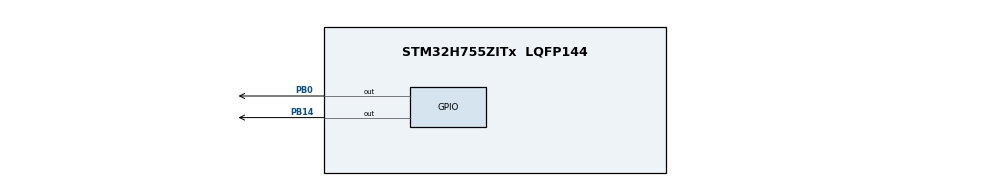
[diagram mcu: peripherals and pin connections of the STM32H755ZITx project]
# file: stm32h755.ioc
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Mcu.Family=STM32H7
PB14.PinAttribute=CortexM4
RCC.PLLSourceVirtual=RCC_PLLSOURCE_CSI
RCC.CortexFreq_Value=76000000
RCC.DIVQ1=4
CortexM4.Pins=PB14
NVIC1.PriorityGroup=NVIC_PRIORITYGROUP_4
RCC.SYSCLKSource=RCC_SYSCLKSOURCE_PLLCLK
ProjectManager.StackSize=0x400
ProjectManager.TargetToolchain=STM32CubeIDE
RCC.HCLKFreq_Value=76000000
RCC.DIVN1=38
RCC.USBFreq_Value=38000000
PB0.PinAttribute=CortexM7
PB14.Signal=GPIO_Output
RCC.HSE_VALUE=8000000
board=NUCLEO-H755ZI-Q
RCC.DIVM1=1
RCC.APB2Freq_Value=76000000
NVIC2.PriorityGroup=NVIC_PRIORITYGROUP_4
RCC.ADCFreq_Value=8062500
VP_SYS_M4_VS_Systick.Mode=SysTick
CortexM7.Pins=PB0
CortexM7.IPs=FATFS_M7\:I,FREERTOS_M7\:I,IWDG1\:I,RCC\:I,WWDG1\:I,DMA\:I,BDMA\:I,MDMA\:I,NVIC1\:I,ETH\:I,USART3\:I,USB_OTG_FS\:I,SYS\:I,CORTEX_M7\:I,DEBUG\:I,USB_DEVICE_M7\:I,USB_HOST_M7\:I,PDM2PCM_M7\:I,PWR\:I,RESMGR_UTILITY\:I,OPENAMP_M7\:I,VREFBUF\:I
Mcu.Name=STM32H755ZITx
RCC.APB3Freq_Value=76000000
RCC.SYSCLKFreq_VALUE=76000000
Mcu.Package=LQFP144
ProjectManager.HeapSize=0x200
RCC.APB4Freq_Value=76000000
RCC.APB1Freq_Value=76000000
PB0.Signal=GPIO_Output
RCC.SupplySource=PWR_DIRECT_SMPS_SUPPLY
CortexM4.IPs=FATFS_M4\:I,FREERTOS_M4\:I,IWDG2\:I,RCC,WWDG2\:I,DMA,BDMA,MDMA,NVIC2\:I,ETH,USART3,DEBUG,USB_DEVICE_M4\:I,USB_HOST_M4\:I,PDM2PCM_M4\:I,PWR,RESMGR_UTILITY,SYS_M4\:I,CORTEX_M4\:I,OPENAMP_M4\:I,VREFBUF

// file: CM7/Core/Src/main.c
/* USER CODE BEGIN Header */
/**
 ******************************************************************************
 * @file           : main.c
 * @brief          : Main program body
 ******************************************************************************
 * @attention
 *
 * <h2><center>&copy; Copyright (c) 2021 STMicroelectronics.
 * All rights reserved.</center></h2>
 *
 * This software component is licensed by ST under BSD 3-Clause license,
 * the "License"; You may not use this file except in compliance with the
 * License. You may obtain a copy of the License at:
 *                        opensource.org/licenses/BSD-3-Clause
 *
 ******************************************************************************
 */
/* USER CODE END Header */
#include "main.h"

/* USER CODE BEGIN PD */

#ifndef HSEM_ID_0
#define HSEM_ID_0 (0U) /* HW semaphore 0*/
#endif
/* USER CODE END PD */

void SystemClock_Config(void);
static void MX_GPIO_Init(void);

int main(void)
{
    /* USER CODE BEGIN Boot_Mode_Sequence_0 */
    int32_t timeout;
    /* USER CODE END Boot_Mode_Sequence_0 */

    /* USER CODE BEGIN Boot_Mode_Sequence_1 */
    /* Wait until CPU2 boots and enters in stop mode or timeout*/
    timeout = 0xFFFF;
    /*
    while ((__HAL_RCC_GET_FLAG(RCC_FLAG_D2CKRDY) != RESET) && (timeout-- > 0))
        ;
    if (timeout < 0)
    {
        Error_Handler();
    }
    */
    /* USER CODE END Boot_Mode_Sequence_1 */
    /* MCU Configuration--------------------------------------------------------*/

    /* Reset of all peripherals, Initializes the Flash interface and the Systick. */
    HAL_Init();

    /* Configure the system clock */
    SystemClock_Config();
    /* USER CODE BEGIN Boot_Mode_Sequence_2 */
    /* When system initialization is finished, Cortex-M7 will release Cortex-M4 by means of
    HSEM notification */
    /*HW semaphore Clock enable*/
    __HAL_RCC_HSEM_CLK_ENABLE();
    /*Take HSEM */
    HAL_HSEM_FastTake(HSEM_ID_0);
    /*Release HSEM in order to notify the CPU2(CM4)*/
    HAL_HSEM_Release(HSEM_ID_0, 0);
    /* wait until CPU2 wakes up from stop mode */
    timeout = 0xFFFF;
    while ((__HAL_RCC_GET_FLAG(RCC_FLAG_D2CKRDY) == RESET) && (timeout-- > 0))
        ;
    if (timeout < 0)
    {
        Error_Handler();
    }
    /* USER CODE END Boot_Mode_Sequence_2 */

    /* USER CODE BEGIN SysInit */
    GPIO_InitTypeDef GPIO_InitStruct = {0};

    /* GPIO Ports Clock Enable */
    __HAL_RCC_GPIOB_CLK_ENABLE();

    /*Configure GPIO pin Output Level */
    HAL_GPIO_WritePin(GPIOB, GPIO_PIN_0, GPIO_PIN_RESET);

    /*Configure GPIO pin : PB0 */
    GPIO_InitStruct.Pin = GPIO_PIN_0;
    GPIO_InitStruct.Mode = GPIO_MODE_OUTPUT_PP;
    GPIO_InitStruct.Pull = GPIO_NOPULL;
    GPIO_InitStruct.Speed = GPIO_SPEED_FREQ_LOW;
    HAL_GPIO_Init(GPIOB, &GPIO_InitStruct);
    /* USER CODE END SysInit */

    /* Initialize all configured peripherals */
    MX_GPIO_Init();

    /* Infinite loop */
    /* USER CODE BEGIN WHILE */
    while (1)
    {
        HAL_GPIO_TogglePin(GPIOB, GPIO_PIN_0);
        HAL_Delay(50);
        /* USER CODE END WHILE */

    }
}

void SystemClock_Config(void)
{
    RCC_OscInitTypeDef RCC_OscInitStruct = {0};
    RCC_ClkInitTypeDef RCC_ClkInitStruct = {0};

    /** Supply configuration update enable
     */
    HAL_PWREx_ConfigSupply(PWR_DIRECT_SMPS_SUPPLY);
    /** Configure the main internal regulator output voltage
     */
    __HAL_PWR_VOLTAGESCALING_CONFIG(PWR_REGULATOR_VOLTAGE_SCALE3);

    while (!__HAL_PWR_GET_FLAG(PWR_FLAG_VOSRDY))
    {
    }
    /** Initializes the RCC Oscillators according to the specified parameters
     * in the RCC_OscInitTypeDef structure.
     */
    RCC_OscInitStruct.OscillatorType = RCC_OSCILLATORTYPE_CSI;
    RCC_OscInitStruct.CSIState = RCC_CSI_ON;
    RCC_OscInitStruct.CSICalibrationValue = RCC_CSICALIBRATION_DEFAULT;
    RCC_OscInitStruct.PLL.PLLState = RCC_PLL_ON;
    RCC_OscInitStruct.PLL.PLLSource = RCC_PLLSOURCE_CSI;
    RCC_OscInitStruct.PLL.PLLM = 1;
    RCC_OscInitStruct.PLL.PLLN = 38;
    RCC_OscInitStruct.PLL.PLLP = 2;
    RCC_OscInitStruct.PLL.PLLQ = 4;
    RCC_OscInitStruct.PLL.PLLR = 2;
    RCC_OscInitStruct.PLL.PLLRGE = RCC_PLL1VCIRANGE_2;
    RCC_OscInitStruct.PLL.PLLVCOSEL = RCC_PLL1VCOMEDIUM;
    RCC_OscInitStruct.PLL.PLLFRACN = 0;
    if (HAL_RCC_OscConfig(&RCC_OscInitStruct) != HAL_OK)
    {
        Error_Handler();
    }
    /** Initializes the CPU, AHB and APB buses clocks
     */
    RCC_ClkInitStruct.ClockType = RCC_CLOCKTYPE_HCLK | RCC_CLOCKTYPE_SYSCLK
                                | RCC_CLOCKTYPE_PCLK1 | RCC_CLOCKTYPE_PCLK2
                                | RCC_CLOCKTYPE_D3PCLK1 | RCC_CLOCKTYPE_D1PCLK1;
    RCC_ClkInitStruct.SYSCLKSource = RCC_SYSCLKSOURCE_PLLCLK;
    RCC_ClkInitStruct.SYSCLKDivider = RCC_SYSCLK_DIV1;
    RCC_ClkInitStruct.AHBCLKDivider = RCC_HCLK_DIV1;
    RCC_ClkInitStruct.APB3CLKDivider = RCC_APB3_DIV1;
    RCC_ClkInitStruct.APB1CLKDivider = RCC_APB1_DIV1;
    RCC_ClkInitStruct.APB2CLKDivider = RCC_APB2_DIV1;
    RCC_ClkInitStruct.APB4CLKDivider = RCC_APB4_DIV1;

    if (HAL_RCC_ClockConfig(&RCC_ClkInitStruct, FLASH_LATENCY_1) != HAL_OK)
    {
        Error_Handler();
    }
}

static void MX_GPIO_Init(void)
{
    GPIO_InitTypeDef GPIO_InitStruct = {0};

    /* GPIO Ports Clock Enable */
    __HAL_RCC_GPIOB_CLK_ENABLE();

    /*Configure GPIO pin Output Level */
    HAL_GPIO_WritePin(GPIOB, GPIO_PIN_0, GPIO_PIN_RESET);

    /*Configure GPIO pin : PB0 */
    GPIO_InitStruct.Pin = GPIO_PIN_0;
    GPIO_InitStruct.Mode = GPIO_MODE_OUTPUT_PP;
    GPIO_InitStruct.Pull = GPIO_NOPULL;
    GPIO_InitStruct.Speed = GPIO_SPEED_FREQ_LOW;
    HAL_GPIO_Init(GPIOB, &GPIO_InitStruct);
}

void Error_Handler(void)
{
    __disable_irq();
    while (1)
    {
    }
}

/************************ (C) COPYRIGHT STMicroelectronics *****END OF FILE****/
